# MCU_NAVSS0_UDMASS_ECC_AGGR0_UDMASS_ECCAGGR0 register map
Vendor: Texas Instruments
Registers are 32-bit, access not given, reset 0x0 unless marked. A register's access mark holds for its fields unless they carry their own. Offsets are as the file gives them; [hi:lo] are bit positions; {n}, {i} and the like mark numbered series.

## MCU_NAVSS0_UDMASS_ECC_AGGR0_UDMASS_ECCAGGR0 (part 4 of 4)
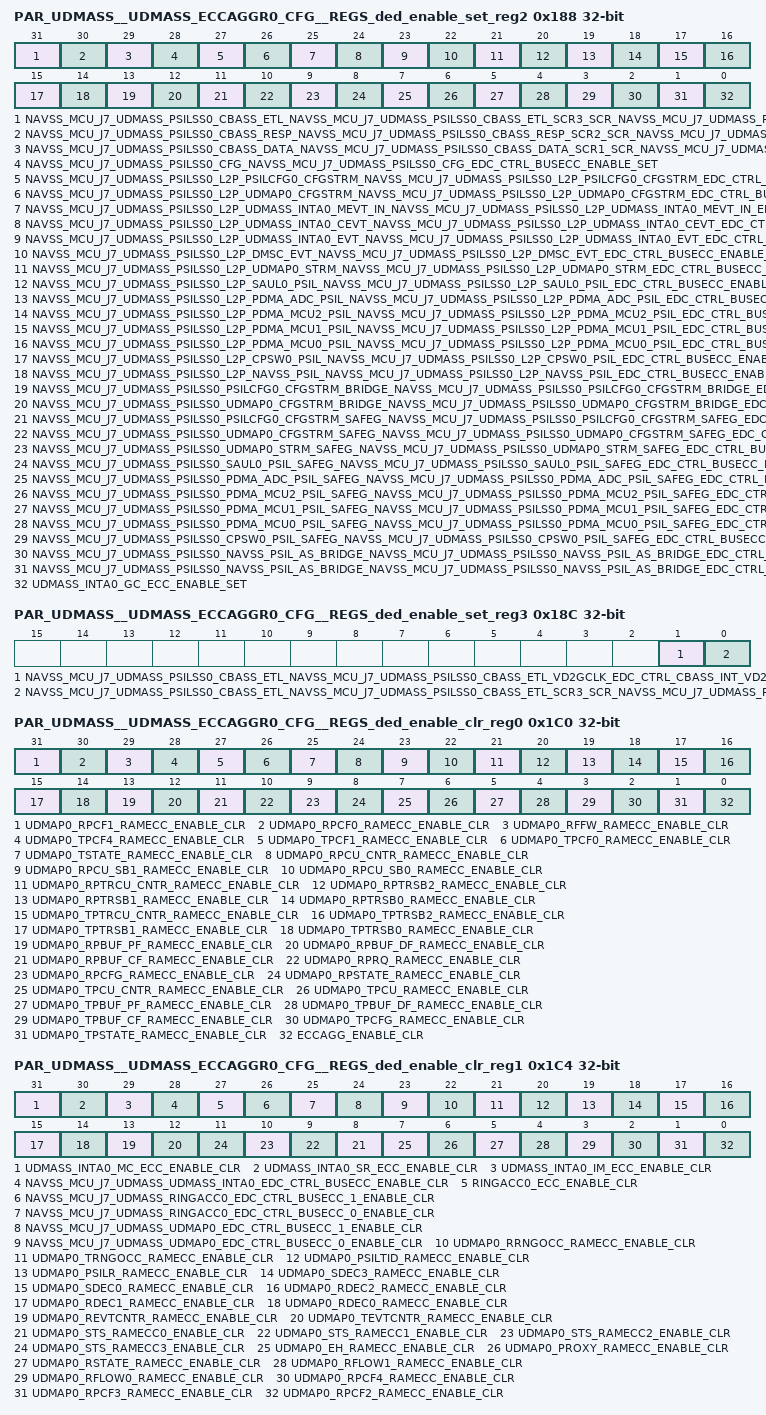
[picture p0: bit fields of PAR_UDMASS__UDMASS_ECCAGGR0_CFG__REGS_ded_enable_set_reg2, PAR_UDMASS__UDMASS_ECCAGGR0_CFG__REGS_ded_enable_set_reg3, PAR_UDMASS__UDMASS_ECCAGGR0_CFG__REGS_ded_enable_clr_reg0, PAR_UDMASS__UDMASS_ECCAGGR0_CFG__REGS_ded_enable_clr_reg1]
0x188 PAR_UDMASS__UDMASS_ECCAGGR0_CFG__REGS_ded_enable_set_reg2 — Interrupt Enable Set Register 2
  [31] NAVSS_MCU_J7_UDMASS_PSILSS0_CBASS_ETL_NAVSS_MCU_J7_UDMASS_PSILSS0_CBASS_ETL_SCR3_SCR_NAVSS_MCU_J7_UDMASS_PSILSS0_CBASS_ETL_SCR3_SCR_EDC_CTRL_BUSECC_0_ENABLE_SET — Interrupt Enable Set Register for navss_mcu_j7_udmass_psilss0_cbass_etl_navss_mcu_j7_udmass_psilss0_cbass_etl_scr3_scr_navss_mcu_j7_udmass_psilss0_cbass_etl_scr3_scr_edc_ctrl_busecc_0_pend (access R/W1TS)
  [30] NAVSS_MCU_J7_UDMASS_PSILSS0_CBASS_RESP_NAVSS_MCU_J7_UDMASS_PSILSS0_CBASS_RESP_SCR2_SCR_NAVSS_MCU_J7_UDMASS_PSILSS0_CBASS_RESP_SCR2_SCR_EDC_CTRL_BUSECC_ENABLE_SET — Interrupt Enable Set Register for navss_mcu_j7_udmass_psilss0_cbass_resp_navss_mcu_j7_udmass_psilss0_cbass_resp_scr2_scr_navss_mcu_j7_udmass_psilss0_cbass_resp_scr2_scr_edc_ctrl_busecc_pend (access R/W1TS)
  [29] NAVSS_MCU_J7_UDMASS_PSILSS0_CBASS_DATA_NAVSS_MCU_J7_UDMASS_PSILSS0_CBASS_DATA_SCR1_SCR_NAVSS_MCU_J7_UDMASS_PSILSS0_CBASS_DATA_SCR1_SCR_EDC_CTRL_BUSECC_ENABLE_SET — Interrupt Enable Set Register for navss_mcu_j7_udmass_psilss0_cbass_data_navss_mcu_j7_udmass_psilss0_cbass_data_scr1_scr_navss_mcu_j7_udmass_psilss0_cbass_data_scr1_scr_edc_ctrl_busecc_pend (access R/W1TS)
  [28] NAVSS_MCU_J7_UDMASS_PSILSS0_CFG_NAVSS_MCU_J7_UDMASS_PSILSS0_CFG_EDC_CTRL_BUSECC_ENABLE_SET — Interrupt Enable Set Register for navss_mcu_j7_udmass_psilss0_cfg_navss_mcu_j7_udmass_psilss0_cfg_edc_ctrl_busecc_pend (access R/W1TS)
  [27] NAVSS_MCU_J7_UDMASS_PSILSS0_L2P_PSILCFG0_CFGSTRM_NAVSS_MCU_J7_UDMASS_PSILSS0_L2P_PSILCFG0_CFGSTRM_EDC_CTRL_BUSECC_ENABLE_SET — Interrupt Enable Set Register for navss_mcu_j7_udmass_psilss0_l2p_psilcfg0_cfgstrm_navss_mcu_j7_udmass_psilss0_l2p_psilcfg0_cfgstrm_edc_ctrl_busecc_pend (access R/W1TS)
  [26] NAVSS_MCU_J7_UDMASS_PSILSS0_L2P_UDMAP0_CFGSTRM_NAVSS_MCU_J7_UDMASS_PSILSS0_L2P_UDMAP0_CFGSTRM_EDC_CTRL_BUSECC_ENABLE_SET — Interrupt Enable Set Register for navss_mcu_j7_udmass_psilss0_l2p_udmap0_cfgstrm_navss_mcu_j7_udmass_psilss0_l2p_udmap0_cfgstrm_edc_ctrl_busecc_pend (access R/W1TS)
  [25] NAVSS_MCU_J7_UDMASS_PSILSS0_L2P_UDMASS_INTA0_MEVT_IN_NAVSS_MCU_J7_UDMASS_PSILSS0_L2P_UDMASS_INTA0_MEVT_IN_EDC_CTRL_BUSECC_ENABLE_SET — Interrupt Enable Set Register for navss_mcu_j7_udmass_psilss0_l2p_udmass_inta0_mevt_in_navss_mcu_j7_udmass_psilss0_l2p_udmass_inta0_mevt_in_edc_ctrl_busecc_pend (access R/W1TS)
  [24] NAVSS_MCU_J7_UDMASS_PSILSS0_L2P_UDMASS_INTA0_CEVT_NAVSS_MCU_J7_UDMASS_PSILSS0_L2P_UDMASS_INTA0_CEVT_EDC_CTRL_BUSECC_ENABLE_SET — Interrupt Enable Set Register for navss_mcu_j7_udmass_psilss0_l2p_udmass_inta0_cevt_navss_mcu_j7_udmass_psilss0_l2p_udmass_inta0_cevt_edc_ctrl_busecc_pend (access R/W1TS)
  [23] NAVSS_MCU_J7_UDMASS_PSILSS0_L2P_UDMASS_INTA0_EVT_NAVSS_MCU_J7_UDMASS_PSILSS0_L2P_UDMASS_INTA0_EVT_EDC_CTRL_BUSECC_ENABLE_SET — Interrupt Enable Set Register for navss_mcu_j7_udmass_psilss0_l2p_udmass_inta0_evt_navss_mcu_j7_udmass_psilss0_l2p_udmass_inta0_evt_edc_ctrl_busecc_pend (access R/W1TS)
  [22] NAVSS_MCU_J7_UDMASS_PSILSS0_L2P_DMSC_EVT_NAVSS_MCU_J7_UDMASS_PSILSS0_L2P_DMSC_EVT_EDC_CTRL_BUSECC_ENABLE_SET — Interrupt Enable Set Register for navss_mcu_j7_udmass_psilss0_l2p_dmsc_evt_navss_mcu_j7_udmass_psilss0_l2p_dmsc_evt_edc_ctrl_busecc_pend (access R/W1TS)
  [21] NAVSS_MCU_J7_UDMASS_PSILSS0_L2P_UDMAP0_STRM_NAVSS_MCU_J7_UDMASS_PSILSS0_L2P_UDMAP0_STRM_EDC_CTRL_BUSECC_ENABLE_SET — Interrupt Enable Set Register for navss_mcu_j7_udmass_psilss0_l2p_udmap0_strm_navss_mcu_j7_udmass_psilss0_l2p_udmap0_strm_edc_ctrl_busecc_pend (access R/W1TS)
  [20] NAVSS_MCU_J7_UDMASS_PSILSS0_L2P_SAUL0_PSIL_NAVSS_MCU_J7_UDMASS_PSILSS0_L2P_SAUL0_PSIL_EDC_CTRL_BUSECC_ENABLE_SET — Interrupt Enable Set Register for navss_mcu_j7_udmass_psilss0_l2p_saul0_psil_navss_mcu_j7_udmass_psilss0_l2p_saul0_psil_edc_ctrl_busecc_pend (access R/W1TS)
  [19] NAVSS_MCU_J7_UDMASS_PSILSS0_L2P_PDMA_ADC_PSIL_NAVSS_MCU_J7_UDMASS_PSILSS0_L2P_PDMA_ADC_PSIL_EDC_CTRL_BUSECC_ENABLE_SET — Interrupt Enable Set Register for navss_mcu_j7_udmass_psilss0_l2p_pdma_adc_psil_navss_mcu_j7_udmass_psilss0_l2p_pdma_adc_psil_edc_ctrl_busecc_pend (access R/W1TS)
  [18] NAVSS_MCU_J7_UDMASS_PSILSS0_L2P_PDMA_MCU2_PSIL_NAVSS_MCU_J7_UDMASS_PSILSS0_L2P_PDMA_MCU2_PSIL_EDC_CTRL_BUSECC_ENABLE_SET — Interrupt Enable Set Register for navss_mcu_j7_udmass_psilss0_l2p_pdma_mcu2_psil_navss_mcu_j7_udmass_psilss0_l2p_pdma_mcu2_psil_edc_ctrl_busecc_pend (access R/W1TS)
  [17] NAVSS_MCU_J7_UDMASS_PSILSS0_L2P_PDMA_MCU1_PSIL_NAVSS_MCU_J7_UDMASS_PSILSS0_L2P_PDMA_MCU1_PSIL_EDC_CTRL_BUSECC_ENABLE_SET — Interrupt Enable Set Register for navss_mcu_j7_udmass_psilss0_l2p_pdma_mcu1_psil_navss_mcu_j7_udmass_psilss0_l2p_pdma_mcu1_psil_edc_ctrl_busecc_pend (access R/W1TS)
  [16] NAVSS_MCU_J7_UDMASS_PSILSS0_L2P_PDMA_MCU0_PSIL_NAVSS_MCU_J7_UDMASS_PSILSS0_L2P_PDMA_MCU0_PSIL_EDC_CTRL_BUSECC_ENABLE_SET — Interrupt Enable Set Register for navss_mcu_j7_udmass_psilss0_l2p_pdma_mcu0_psil_navss_mcu_j7_udmass_psilss0_l2p_pdma_mcu0_psil_edc_ctrl_busecc_pend (access R/W1TS)
  [15] NAVSS_MCU_J7_UDMASS_PSILSS0_L2P_CPSW0_PSIL_NAVSS_MCU_J7_UDMASS_PSILSS0_L2P_CPSW0_PSIL_EDC_CTRL_BUSECC_ENABLE_SET — Interrupt Enable Set Register for navss_mcu_j7_udmass_psilss0_l2p_cpsw0_psil_navss_mcu_j7_udmass_psilss0_l2p_cpsw0_psil_edc_ctrl_busecc_pend (access R/W1TS)
  [14] NAVSS_MCU_J7_UDMASS_PSILSS0_L2P_NAVSS_PSIL_NAVSS_MCU_J7_UDMASS_PSILSS0_L2P_NAVSS_PSIL_EDC_CTRL_BUSECC_ENABLE_SET — Interrupt Enable Set Register for navss_mcu_j7_udmass_psilss0_l2p_navss_psil_navss_mcu_j7_udmass_psilss0_l2p_navss_psil_edc_ctrl_busecc_pend (access R/W1TS)
  [13] NAVSS_MCU_J7_UDMASS_PSILSS0_PSILCFG0_CFGSTRM_BRIDGE_NAVSS_MCU_J7_UDMASS_PSILSS0_PSILCFG0_CFGSTRM_BRIDGE_EDC_CTRL_BUSECC_ENABLE_SET — Interrupt Enable Set Register for navss_mcu_j7_udmass_psilss0_psilcfg0_cfgstrm_bridge_navss_mcu_j7_udmass_psilss0_psilcfg0_cfgstrm_bridge_edc_ctrl_busecc_pend (access R/W1TS)
  [12] NAVSS_MCU_J7_UDMASS_PSILSS0_UDMAP0_CFGSTRM_BRIDGE_NAVSS_MCU_J7_UDMASS_PSILSS0_UDMAP0_CFGSTRM_BRIDGE_EDC_CTRL_BUSECC_ENABLE_SET — Interrupt Enable Set Register for navss_mcu_j7_udmass_psilss0_udmap0_cfgstrm_bridge_navss_mcu_j7_udmass_psilss0_udmap0_cfgstrm_bridge_edc_ctrl_busecc_pend (access R/W1TS)
  [11] NAVSS_MCU_J7_UDMASS_PSILSS0_PSILCFG0_CFGSTRM_SAFEG_NAVSS_MCU_J7_UDMASS_PSILSS0_PSILCFG0_CFGSTRM_SAFEG_EDC_CTRL_BUSECC_ENABLE_SET — Interrupt Enable Set Register for navss_mcu_j7_udmass_psilss0_psilcfg0_cfgstrm_safeg_navss_mcu_j7_udmass_psilss0_psilcfg0_cfgstrm_safeg_edc_ctrl_busecc_pend (access R/W1TS)
  [10] NAVSS_MCU_J7_UDMASS_PSILSS0_UDMAP0_CFGSTRM_SAFEG_NAVSS_MCU_J7_UDMASS_PSILSS0_UDMAP0_CFGSTRM_SAFEG_EDC_CTRL_BUSECC_ENABLE_SET — Interrupt Enable Set Register for navss_mcu_j7_udmass_psilss0_udmap0_cfgstrm_safeg_navss_mcu_j7_udmass_psilss0_udmap0_cfgstrm_safeg_edc_ctrl_busecc_pend (access R/W1TS)
  [9] NAVSS_MCU_J7_UDMASS_PSILSS0_UDMAP0_STRM_SAFEG_NAVSS_MCU_J7_UDMASS_PSILSS0_UDMAP0_STRM_SAFEG_EDC_CTRL_BUSECC_ENABLE_SET — Interrupt Enable Set Register for navss_mcu_j7_udmass_psilss0_udmap0_strm_safeg_navss_mcu_j7_udmass_psilss0_udmap0_strm_safeg_edc_ctrl_busecc_pend (access R/W1TS)
  [8] NAVSS_MCU_J7_UDMASS_PSILSS0_SAUL0_PSIL_SAFEG_NAVSS_MCU_J7_UDMASS_PSILSS0_SAUL0_PSIL_SAFEG_EDC_CTRL_BUSECC_ENABLE_SET — Interrupt Enable Set Register for navss_mcu_j7_udmass_psilss0_saul0_psil_safeg_navss_mcu_j7_udmass_psilss0_saul0_psil_safeg_edc_ctrl_busecc_pend (access R/W1TS)
  [7] NAVSS_MCU_J7_UDMASS_PSILSS0_PDMA_ADC_PSIL_SAFEG_NAVSS_MCU_J7_UDMASS_PSILSS0_PDMA_ADC_PSIL_SAFEG_EDC_CTRL_BUSECC_ENABLE_SET — Interrupt Enable Set Register for navss_mcu_j7_udmass_psilss0_pdma_adc_psil_safeg_navss_mcu_j7_udmass_psilss0_pdma_adc_psil_safeg_edc_ctrl_busecc_pend (access R/W1TS)
  [6] NAVSS_MCU_J7_UDMASS_PSILSS0_PDMA_MCU2_PSIL_SAFEG_NAVSS_MCU_J7_UDMASS_PSILSS0_PDMA_MCU2_PSIL_SAFEG_EDC_CTRL_BUSECC_ENABLE_SET — Interrupt Enable Set Register for navss_mcu_j7_udmass_psilss0_pdma_mcu2_psil_safeg_navss_mcu_j7_udmass_psilss0_pdma_mcu2_psil_safeg_edc_ctrl_busecc_pend (access R/W1TS)
  [5] NAVSS_MCU_J7_UDMASS_PSILSS0_PDMA_MCU1_PSIL_SAFEG_NAVSS_MCU_J7_UDMASS_PSILSS0_PDMA_MCU1_PSIL_SAFEG_EDC_CTRL_BUSECC_ENABLE_SET — Interrupt Enable Set Register for navss_mcu_j7_udmass_psilss0_pdma_mcu1_psil_safeg_navss_mcu_j7_udmass_psilss0_pdma_mcu1_psil_safeg_edc_ctrl_busecc_pend (access R/W1TS)
  [4] NAVSS_MCU_J7_UDMASS_PSILSS0_PDMA_MCU0_PSIL_SAFEG_NAVSS_MCU_J7_UDMASS_PSILSS0_PDMA_MCU0_PSIL_SAFEG_EDC_CTRL_BUSECC_ENABLE_SET — Interrupt Enable Set Register for navss_mcu_j7_udmass_psilss0_pdma_mcu0_psil_safeg_navss_mcu_j7_udmass_psilss0_pdma_mcu0_psil_safeg_edc_ctrl_busecc_pend (access R/W1TS)
  [3] NAVSS_MCU_J7_UDMASS_PSILSS0_CPSW0_PSIL_SAFEG_NAVSS_MCU_J7_UDMASS_PSILSS0_CPSW0_PSIL_SAFEG_EDC_CTRL_BUSECC_ENABLE_SET — Interrupt Enable Set Register for navss_mcu_j7_udmass_psilss0_cpsw0_psil_safeg_navss_mcu_j7_udmass_psilss0_cpsw0_psil_safeg_edc_ctrl_busecc_pend (access R/W1TS)
  [2] NAVSS_MCU_J7_UDMASS_PSILSS0_NAVSS_PSIL_AS_BRIDGE_NAVSS_MCU_J7_UDMASS_PSILSS0_NAVSS_PSIL_AS_BRIDGE_EDC_CTRL_NAVSS_PSIL_SCR_E_GCLK_BUSECC_ENABLE_SET — Interrupt Enable Set Register for navss_mcu_j7_udmass_psilss0_navss_psil_as_bridge_navss_mcu_j7_udmass_psilss0_navss_psil_as_bridge_edc_ctrl_navss_psil_scr_e_gclk_busecc_pend (access R/W1TS)
  [1] NAVSS_MCU_J7_UDMASS_PSILSS0_NAVSS_PSIL_AS_BRIDGE_NAVSS_MCU_J7_UDMASS_PSILSS0_NAVSS_PSIL_AS_BRIDGE_EDC_CTRL_NAVSS_PSIL_E_GCLK_BUSECC_ENABLE_SET — Interrupt Enable Set Register for navss_mcu_j7_udmass_psilss0_navss_psil_as_bridge_navss_mcu_j7_udmass_psilss0_navss_psil_as_bridge_edc_ctrl_navss_psil_e_gclk_busecc_pend (access R/W1TS)
  [0] UDMASS_INTA0_GC_ECC_ENABLE_SET — Interrupt Enable Set Register for udmass_inta0_gc_ecc_pend (access R/W1TS)
0x18C PAR_UDMASS__UDMASS_ECCAGGR0_CFG__REGS_ded_enable_set_reg3 — Interrupt Enable Set Register 3
  [1] NAVSS_MCU_J7_UDMASS_PSILSS0_CBASS_ETL_NAVSS_MCU_J7_UDMASS_PSILSS0_CBASS_ETL_VD2GCLK_EDC_CTRL_CBASS_INT_VD2GBUSECC_ENABLE_SET — Interrupt Enable Set Register for navss_mcu_j7_udmass_psilss0_cbass_etl_navss_mcu_j7_udmass_psilss0_cbass_etl_vd2gclk_edc_ctrl_cbass_int_vd2gbusecc_pend (access R/W1TS)
  [0] NAVSS_MCU_J7_UDMASS_PSILSS0_CBASS_ETL_NAVSS_MCU_J7_UDMASS_PSILSS0_CBASS_ETL_SCR3_SCR_NAVSS_MCU_J7_UDMASS_PSILSS0_CBASS_ETL_SCR3_SCR_EDC_CTRL_BUSECC_1_ENABLE_SET — Interrupt Enable Set Register for navss_mcu_j7_udmass_psilss0_cbass_etl_navss_mcu_j7_udmass_psilss0_cbass_etl_scr3_scr_navss_mcu_j7_udmass_psilss0_cbass_etl_scr3_scr_edc_ctrl_busecc_1_pend (access R/W1TS)
0x1C0 PAR_UDMASS__UDMASS_ECCAGGR0_CFG__REGS_ded_enable_clr_reg0 — Interrupt Enable Clear Register 0
  [31] UDMAP0_RPCF1_RAMECC_ENABLE_CLR — Interrupt Enable Clear Register for udmap0_rpcf1_ramecc_pend (access R/W1TC)
  [30] UDMAP0_RPCF0_RAMECC_ENABLE_CLR — Interrupt Enable Clear Register for udmap0_rpcf0_ramecc_pend (access R/W1TC)
  [29] UDMAP0_RFFW_RAMECC_ENABLE_CLR — Interrupt Enable Clear Register for udmap0_rffw_ramecc_pend (access R/W1TC)
  [28] UDMAP0_TPCF4_RAMECC_ENABLE_CLR — Interrupt Enable Clear Register for udmap0_tpcf4_ramecc_pend (access R/W1TC)
  [27] UDMAP0_TPCF1_RAMECC_ENABLE_CLR — Interrupt Enable Clear Register for udmap0_tpcf1_ramecc_pend (access R/W1TC)
  [26] UDMAP0_TPCF0_RAMECC_ENABLE_CLR — Interrupt Enable Clear Register for udmap0_tpcf0_ramecc_pend (access R/W1TC)
  [25] UDMAP0_TSTATE_RAMECC_ENABLE_CLR — Interrupt Enable Clear Register for udmap0_tstate_ramecc_pend (access R/W1TC)
  [24] UDMAP0_RPCU_CNTR_RAMECC_ENABLE_CLR — Interrupt Enable Clear Register for udmap0_rpcu_cntr_ramecc_pend (access R/W1TC)
  [23] UDMAP0_RPCU_SB1_RAMECC_ENABLE_CLR — Interrupt Enable Clear Register for udmap0_rpcu_sb1_ramecc_pend (access R/W1TC)
  [22] UDMAP0_RPCU_SB0_RAMECC_ENABLE_CLR — Interrupt Enable Clear Register for udmap0_rpcu_sb0_ramecc_pend (access R/W1TC)
  [21] UDMAP0_RPTRCU_CNTR_RAMECC_ENABLE_CLR — Interrupt Enable Clear Register for udmap0_rptrcu_cntr_ramecc_pend (access R/W1TC)
  [20] UDMAP0_RPTRSB2_RAMECC_ENABLE_CLR — Interrupt Enable Clear Register for udmap0_rptrsb2_ramecc_pend (access R/W1TC)
  [19] UDMAP0_RPTRSB1_RAMECC_ENABLE_CLR — Interrupt Enable Clear Register for udmap0_rptrsb1_ramecc_pend (access R/W1TC)
  [18] UDMAP0_RPTRSB0_RAMECC_ENABLE_CLR — Interrupt Enable Clear Register for udmap0_rptrsb0_ramecc_pend (access R/W1TC)
  [17] UDMAP0_TPTRCU_CNTR_RAMECC_ENABLE_CLR — Interrupt Enable Clear Register for udmap0_tptrcu_cntr_ramecc_pend (access R/W1TC)
  [16] UDMAP0_TPTRSB2_RAMECC_ENABLE_CLR — Interrupt Enable Clear Register for udmap0_tptrsb2_ramecc_pend (access R/W1TC)
  [15] UDMAP0_TPTRSB1_RAMECC_ENABLE_CLR — Interrupt Enable Clear Register for udmap0_tptrsb1_ramecc_pend (access R/W1TC)
  [14] UDMAP0_TPTRSB0_RAMECC_ENABLE_CLR — Interrupt Enable Clear Register for udmap0_tptrsb0_ramecc_pend (access R/W1TC)
  [13] UDMAP0_RPBUF_PF_RAMECC_ENABLE_CLR — Interrupt Enable Clear Register for udmap0_rpbuf_pf_ramecc_pend (access R/W1TC)
  [12] UDMAP0_RPBUF_DF_RAMECC_ENABLE_CLR — Interrupt Enable Clear Register for udmap0_rpbuf_df_ramecc_pend (access R/W1TC)
  [11] UDMAP0_RPBUF_CF_RAMECC_ENABLE_CLR — Interrupt Enable Clear Register for udmap0_rpbuf_cf_ramecc_pend (access R/W1TC)
  [10] UDMAP0_RPRQ_RAMECC_ENABLE_CLR — Interrupt Enable Clear Register for udmap0_rprq_ramecc_pend (access R/W1TC)
  [9] UDMAP0_RPCFG_RAMECC_ENABLE_CLR — Interrupt Enable Clear Register for udmap0_rpcfg_ramecc_pend (access R/W1TC)
  [8] UDMAP0_RPSTATE_RAMECC_ENABLE_CLR — Interrupt Enable Clear Register for udmap0_rpstate_ramecc_pend (access R/W1TC)
  [7] UDMAP0_TPCU_CNTR_RAMECC_ENABLE_CLR — Interrupt Enable Clear Register for udmap0_tpcu_cntr_ramecc_pend (access R/W1TC)
  [6] UDMAP0_TPCU_RAMECC_ENABLE_CLR — Interrupt Enable Clear Register for udmap0_tpcu_ramecc_pend (access R/W1TC)
  [5] UDMAP0_TPBUF_PF_RAMECC_ENABLE_CLR — Interrupt Enable Clear Register for udmap0_tpbuf_pf_ramecc_pend (access R/W1TC)
  [4] UDMAP0_TPBUF_DF_RAMECC_ENABLE_CLR — Interrupt Enable Clear Register for udmap0_tpbuf_df_ramecc_pend (access R/W1TC)
  [3] UDMAP0_TPBUF_CF_RAMECC_ENABLE_CLR — Interrupt Enable Clear Register for udmap0_tpbuf_cf_ramecc_pend (access R/W1TC)
  [2] UDMAP0_TPCFG_RAMECC_ENABLE_CLR — Interrupt Enable Clear Register for udmap0_tpcfg_ramecc_pend (access R/W1TC)
  [1] UDMAP0_TPSTATE_RAMECC_ENABLE_CLR — Interrupt Enable Clear Register for udmap0_tpstate_ramecc_pend (access R/W1TC)
  [0] ECCAGG_ENABLE_CLR — Interrupt Enable Clear Register for eccagg_pend (access R/W1TC)
0x1C4 PAR_UDMASS__UDMASS_ECCAGGR0_CFG__REGS_ded_enable_clr_reg1 — Interrupt Enable Clear Register 1
  [31] UDMASS_INTA0_MC_ECC_ENABLE_CLR — Interrupt Enable Clear Register for udmass_inta0_mc_ecc_pend (access R/W1TC)
  [30] UDMASS_INTA0_SR_ECC_ENABLE_CLR — Interrupt Enable Clear Register for udmass_inta0_sr_ecc_pend (access R/W1TC)
  [29] UDMASS_INTA0_IM_ECC_ENABLE_CLR — Interrupt Enable Clear Register for udmass_inta0_im_ecc_pend (access R/W1TC)
  [28] NAVSS_MCU_J7_UDMASS_UDMASS_INTA0_EDC_CTRL_BUSECC_ENABLE_CLR — Interrupt Enable Clear Register for navss_mcu_j7_udmass_udmass_inta0_edc_ctrl_busecc_pend (access R/W1TC)
  [27] RINGACC0_ECC_ENABLE_CLR — Interrupt Enable Clear Register for ringacc0_ecc_pend (access R/W1TC)
  [26] NAVSS_MCU_J7_UDMASS_RINGACC0_EDC_CTRL_BUSECC_1_ENABLE_CLR — Interrupt Enable Clear Register for navss_mcu_j7_udmass_ringacc0_edc_ctrl_busecc_1_pend (access R/W1TC)
  [25] NAVSS_MCU_J7_UDMASS_RINGACC0_EDC_CTRL_BUSECC_0_ENABLE_CLR — Interrupt Enable Clear Register for navss_mcu_j7_udmass_ringacc0_edc_ctrl_busecc_0_pend (access R/W1TC)
  [24] NAVSS_MCU_J7_UDMASS_UDMAP0_EDC_CTRL_BUSECC_1_ENABLE_CLR — Interrupt Enable Clear Register for navss_mcu_j7_udmass_udmap0_edc_ctrl_busecc_1_pend (access R/W1TC)
  [23] NAVSS_MCU_J7_UDMASS_UDMAP0_EDC_CTRL_BUSECC_0_ENABLE_CLR — Interrupt Enable Clear Register for navss_mcu_j7_udmass_udmap0_edc_ctrl_busecc_0_pend (access R/W1TC)
  [22] UDMAP0_RRNGOCC_RAMECC_ENABLE_CLR — Interrupt Enable Clear Register for udmap0_rrngocc_ramecc_pend (access R/W1TC)
  [21] UDMAP0_TRNGOCC_RAMECC_ENABLE_CLR — Interrupt Enable Clear Register for udmap0_trngocc_ramecc_pend (access R/W1TC)
  [20] UDMAP0_PSILTID_RAMECC_ENABLE_CLR — Interrupt Enable Clear Register for udmap0_psiltid_ramecc_pend (access R/W1TC)
  [19] UDMAP0_PSILR_RAMECC_ENABLE_CLR — Interrupt Enable Clear Register for udmap0_psilr_ramecc_pend (access R/W1TC)
  [18] UDMAP0_SDEC3_RAMECC_ENABLE_CLR — Interrupt Enable Clear Register for udmap0_sdec3_ramecc_pend (access R/W1TC)
  [17] UDMAP0_SDEC0_RAMECC_ENABLE_CLR — Interrupt Enable Clear Register for udmap0_sdec0_ramecc_pend (access R/W1TC)
  [16] UDMAP0_RDEC2_RAMECC_ENABLE_CLR — Interrupt Enable Clear Register for udmap0_rdec2_ramecc_pend (access R/W1TC)
  [15] UDMAP0_RDEC1_RAMECC_ENABLE_CLR — Interrupt Enable Clear Register for udmap0_rdec1_ramecc_pend (access R/W1TC)
  [14] UDMAP0_RDEC0_RAMECC_ENABLE_CLR — Interrupt Enable Clear Register for udmap0_rdec0_ramecc_pend (access R/W1TC)
  [13] UDMAP0_REVTCNTR_RAMECC_ENABLE_CLR — Interrupt Enable Clear Register for udmap0_revtcntr_ramecc_pend (access R/W1TC)
  [12] UDMAP0_TEVTCNTR_RAMECC_ENABLE_CLR — Interrupt Enable Clear Register for udmap0_tevtcntr_ramecc_pend (access R/W1TC)
  [n+8] UDMAP0_STS_RAMECC{n}_ENABLE_CLR (n=0..3) — Interrupt Enable Clear Register for udmap0_sts_ramecc{n}_pend (access R/W1TC)
  [7] UDMAP0_EH_RAMECC_ENABLE_CLR — Interrupt Enable Clear Register for udmap0_eh_ramecc_pend (access R/W1TC)
  [6] UDMAP0_PROXY_RAMECC_ENABLE_CLR — Interrupt Enable Clear Register for udmap0_proxy_ramecc_pend (access R/W1TC)
  [5] UDMAP0_RSTATE_RAMECC_ENABLE_CLR — Interrupt Enable Clear Register for udmap0_rstate_ramecc_pend (access R/W1TC)
  [4] UDMAP0_RFLOW1_RAMECC_ENABLE_CLR — Interrupt Enable Clear Register for udmap0_rflow1_ramecc_pend (access R/W1TC)
  [3] UDMAP0_RFLOW0_RAMECC_ENABLE_CLR — Interrupt Enable Clear Register for udmap0_rflow0_ramecc_pend (access R/W1TC)
  [2] UDMAP0_RPCF4_RAMECC_ENABLE_CLR — Interrupt Enable Clear Register for udmap0_rpcf4_ramecc_pend (access R/W1TC)
  [1] UDMAP0_RPCF3_RAMECC_ENABLE_CLR — Interrupt Enable Clear Register for udmap0_rpcf3_ramecc_pend (access R/W1TC)
  [0] UDMAP0_RPCF2_RAMECC_ENABLE_CLR — Interrupt Enable Clear Register for udmap0_rpcf2_ramecc_pend (access R/W1TC)
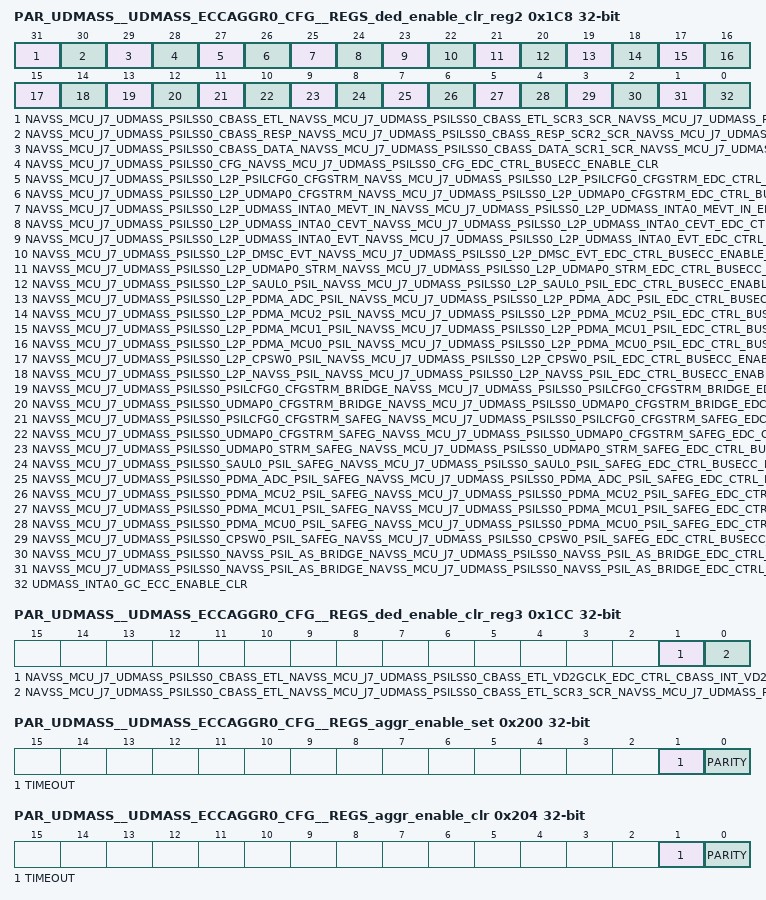
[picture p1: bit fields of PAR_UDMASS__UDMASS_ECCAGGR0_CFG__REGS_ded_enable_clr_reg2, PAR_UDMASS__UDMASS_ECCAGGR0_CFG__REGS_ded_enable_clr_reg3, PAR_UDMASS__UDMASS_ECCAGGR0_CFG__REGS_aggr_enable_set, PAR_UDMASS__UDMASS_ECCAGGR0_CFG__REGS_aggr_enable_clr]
0x1C8 PAR_UDMASS__UDMASS_ECCAGGR0_CFG__REGS_ded_enable_clr_reg2 — Interrupt Enable Clear Register 2
  [31] NAVSS_MCU_J7_UDMASS_PSILSS0_CBASS_ETL_NAVSS_MCU_J7_UDMASS_PSILSS0_CBASS_ETL_SCR3_SCR_NAVSS_MCU_J7_UDMASS_PSILSS0_CBASS_ETL_SCR3_SCR_EDC_CTRL_BUSECC_0_ENABLE_CLR — Interrupt Enable Clear Register for navss_mcu_j7_udmass_psilss0_cbass_etl_navss_mcu_j7_udmass_psilss0_cbass_etl_scr3_scr_navss_mcu_j7_udmass_psilss0_cbass_etl_scr3_scr_edc_ctrl_busecc_0_pend (access R/W1TC)
  [30] NAVSS_MCU_J7_UDMASS_PSILSS0_CBASS_RESP_NAVSS_MCU_J7_UDMASS_PSILSS0_CBASS_RESP_SCR2_SCR_NAVSS_MCU_J7_UDMASS_PSILSS0_CBASS_RESP_SCR2_SCR_EDC_CTRL_BUSECC_ENABLE_CLR — Interrupt Enable Clear Register for navss_mcu_j7_udmass_psilss0_cbass_resp_navss_mcu_j7_udmass_psilss0_cbass_resp_scr2_scr_navss_mcu_j7_udmass_psilss0_cbass_resp_scr2_scr_edc_ctrl_busecc_pend (access R/W1TC)
  [29] NAVSS_MCU_J7_UDMASS_PSILSS0_CBASS_DATA_NAVSS_MCU_J7_UDMASS_PSILSS0_CBASS_DATA_SCR1_SCR_NAVSS_MCU_J7_UDMASS_PSILSS0_CBASS_DATA_SCR1_SCR_EDC_CTRL_BUSECC_ENABLE_CLR — Interrupt Enable Clear Register for navss_mcu_j7_udmass_psilss0_cbass_data_navss_mcu_j7_udmass_psilss0_cbass_data_scr1_scr_navss_mcu_j7_udmass_psilss0_cbass_data_scr1_scr_edc_ctrl_busecc_pend (access R/W1TC)
  [28] NAVSS_MCU_J7_UDMASS_PSILSS0_CFG_NAVSS_MCU_J7_UDMASS_PSILSS0_CFG_EDC_CTRL_BUSECC_ENABLE_CLR — Interrupt Enable Clear Register for navss_mcu_j7_udmass_psilss0_cfg_navss_mcu_j7_udmass_psilss0_cfg_edc_ctrl_busecc_pend (access R/W1TC)
  [27] NAVSS_MCU_J7_UDMASS_PSILSS0_L2P_PSILCFG0_CFGSTRM_NAVSS_MCU_J7_UDMASS_PSILSS0_L2P_PSILCFG0_CFGSTRM_EDC_CTRL_BUSECC_ENABLE_CLR — Interrupt Enable Clear Register for navss_mcu_j7_udmass_psilss0_l2p_psilcfg0_cfgstrm_navss_mcu_j7_udmass_psilss0_l2p_psilcfg0_cfgstrm_edc_ctrl_busecc_pend (access R/W1TC)
  [26] NAVSS_MCU_J7_UDMASS_PSILSS0_L2P_UDMAP0_CFGSTRM_NAVSS_MCU_J7_UDMASS_PSILSS0_L2P_UDMAP0_CFGSTRM_EDC_CTRL_BUSECC_ENABLE_CLR — Interrupt Enable Clear Register for navss_mcu_j7_udmass_psilss0_l2p_udmap0_cfgstrm_navss_mcu_j7_udmass_psilss0_l2p_udmap0_cfgstrm_edc_ctrl_busecc_pend (access R/W1TC)
  [25] NAVSS_MCU_J7_UDMASS_PSILSS0_L2P_UDMASS_INTA0_MEVT_IN_NAVSS_MCU_J7_UDMASS_PSILSS0_L2P_UDMASS_INTA0_MEVT_IN_EDC_CTRL_BUSECC_ENABLE_CLR — Interrupt Enable Clear Register for navss_mcu_j7_udmass_psilss0_l2p_udmass_inta0_mevt_in_navss_mcu_j7_udmass_psilss0_l2p_udmass_inta0_mevt_in_edc_ctrl_busecc_pend (access R/W1TC)
  [24] NAVSS_MCU_J7_UDMASS_PSILSS0_L2P_UDMASS_INTA0_CEVT_NAVSS_MCU_J7_UDMASS_PSILSS0_L2P_UDMASS_INTA0_CEVT_EDC_CTRL_BUSECC_ENABLE_CLR — Interrupt Enable Clear Register for navss_mcu_j7_udmass_psilss0_l2p_udmass_inta0_cevt_navss_mcu_j7_udmass_psilss0_l2p_udmass_inta0_cevt_edc_ctrl_busecc_pend (access R/W1TC)
  [23] NAVSS_MCU_J7_UDMASS_PSILSS0_L2P_UDMASS_INTA0_EVT_NAVSS_MCU_J7_UDMASS_PSILSS0_L2P_UDMASS_INTA0_EVT_EDC_CTRL_BUSECC_ENABLE_CLR — Interrupt Enable Clear Register for navss_mcu_j7_udmass_psilss0_l2p_udmass_inta0_evt_navss_mcu_j7_udmass_psilss0_l2p_udmass_inta0_evt_edc_ctrl_busecc_pend (access R/W1TC)
  [22] NAVSS_MCU_J7_UDMASS_PSILSS0_L2P_DMSC_EVT_NAVSS_MCU_J7_UDMASS_PSILSS0_L2P_DMSC_EVT_EDC_CTRL_BUSECC_ENABLE_CLR — Interrupt Enable Clear Register for navss_mcu_j7_udmass_psilss0_l2p_dmsc_evt_navss_mcu_j7_udmass_psilss0_l2p_dmsc_evt_edc_ctrl_busecc_pend (access R/W1TC)
  [21] NAVSS_MCU_J7_UDMASS_PSILSS0_L2P_UDMAP0_STRM_NAVSS_MCU_J7_UDMASS_PSILSS0_L2P_UDMAP0_STRM_EDC_CTRL_BUSECC_ENABLE_CLR — Interrupt Enable Clear Register for navss_mcu_j7_udmass_psilss0_l2p_udmap0_strm_navss_mcu_j7_udmass_psilss0_l2p_udmap0_strm_edc_ctrl_busecc_pend (access R/W1TC)
  [20] NAVSS_MCU_J7_UDMASS_PSILSS0_L2P_SAUL0_PSIL_NAVSS_MCU_J7_UDMASS_PSILSS0_L2P_SAUL0_PSIL_EDC_CTRL_BUSECC_ENABLE_CLR — Interrupt Enable Clear Register for navss_mcu_j7_udmass_psilss0_l2p_saul0_psil_navss_mcu_j7_udmass_psilss0_l2p_saul0_psil_edc_ctrl_busecc_pend (access R/W1TC)
  [19] NAVSS_MCU_J7_UDMASS_PSILSS0_L2P_PDMA_ADC_PSIL_NAVSS_MCU_J7_UDMASS_PSILSS0_L2P_PDMA_ADC_PSIL_EDC_CTRL_BUSECC_ENABLE_CLR — Interrupt Enable Clear Register for navss_mcu_j7_udmass_psilss0_l2p_pdma_adc_psil_navss_mcu_j7_udmass_psilss0_l2p_pdma_adc_psil_edc_ctrl_busecc_pend (access R/W1TC)
  [18] NAVSS_MCU_J7_UDMASS_PSILSS0_L2P_PDMA_MCU2_PSIL_NAVSS_MCU_J7_UDMASS_PSILSS0_L2P_PDMA_MCU2_PSIL_EDC_CTRL_BUSECC_ENABLE_CLR — Interrupt Enable Clear Register for navss_mcu_j7_udmass_psilss0_l2p_pdma_mcu2_psil_navss_mcu_j7_udmass_psilss0_l2p_pdma_mcu2_psil_edc_ctrl_busecc_pend (access R/W1TC)
  [17] NAVSS_MCU_J7_UDMASS_PSILSS0_L2P_PDMA_MCU1_PSIL_NAVSS_MCU_J7_UDMASS_PSILSS0_L2P_PDMA_MCU1_PSIL_EDC_CTRL_BUSECC_ENABLE_CLR — Interrupt Enable Clear Register for navss_mcu_j7_udmass_psilss0_l2p_pdma_mcu1_psil_navss_mcu_j7_udmass_psilss0_l2p_pdma_mcu1_psil_edc_ctrl_busecc_pend (access R/W1TC)
  [16] NAVSS_MCU_J7_UDMASS_PSILSS0_L2P_PDMA_MCU0_PSIL_NAVSS_MCU_J7_UDMASS_PSILSS0_L2P_PDMA_MCU0_PSIL_EDC_CTRL_BUSECC_ENABLE_CLR — Interrupt Enable Clear Register for navss_mcu_j7_udmass_psilss0_l2p_pdma_mcu0_psil_navss_mcu_j7_udmass_psilss0_l2p_pdma_mcu0_psil_edc_ctrl_busecc_pend (access R/W1TC)
  [15] NAVSS_MCU_J7_UDMASS_PSILSS0_L2P_CPSW0_PSIL_NAVSS_MCU_J7_UDMASS_PSILSS0_L2P_CPSW0_PSIL_EDC_CTRL_BUSECC_ENABLE_CLR — Interrupt Enable Clear Register for navss_mcu_j7_udmass_psilss0_l2p_cpsw0_psil_navss_mcu_j7_udmass_psilss0_l2p_cpsw0_psil_edc_ctrl_busecc_pend (access R/W1TC)
  [14] NAVSS_MCU_J7_UDMASS_PSILSS0_L2P_NAVSS_PSIL_NAVSS_MCU_J7_UDMASS_PSILSS0_L2P_NAVSS_PSIL_EDC_CTRL_BUSECC_ENABLE_CLR — Interrupt Enable Clear Register for navss_mcu_j7_udmass_psilss0_l2p_navss_psil_navss_mcu_j7_udmass_psilss0_l2p_navss_psil_edc_ctrl_busecc_pend (access R/W1TC)
  [13] NAVSS_MCU_J7_UDMASS_PSILSS0_PSILCFG0_CFGSTRM_BRIDGE_NAVSS_MCU_J7_UDMASS_PSILSS0_PSILCFG0_CFGSTRM_BRIDGE_EDC_CTRL_BUSECC_ENABLE_CLR — Interrupt Enable Clear Register for navss_mcu_j7_udmass_psilss0_psilcfg0_cfgstrm_bridge_navss_mcu_j7_udmass_psilss0_psilcfg0_cfgstrm_bridge_edc_ctrl_busecc_pend (access R/W1TC)
  [12] NAVSS_MCU_J7_UDMASS_PSILSS0_UDMAP0_CFGSTRM_BRIDGE_NAVSS_MCU_J7_UDMASS_PSILSS0_UDMAP0_CFGSTRM_BRIDGE_EDC_CTRL_BUSECC_ENABLE_CLR — Interrupt Enable Clear Register for navss_mcu_j7_udmass_psilss0_udmap0_cfgstrm_bridge_navss_mcu_j7_udmass_psilss0_udmap0_cfgstrm_bridge_edc_ctrl_busecc_pend (access R/W1TC)
  [11] NAVSS_MCU_J7_UDMASS_PSILSS0_PSILCFG0_CFGSTRM_SAFEG_NAVSS_MCU_J7_UDMASS_PSILSS0_PSILCFG0_CFGSTRM_SAFEG_EDC_CTRL_BUSECC_ENABLE_CLR — Interrupt Enable Clear Register for navss_mcu_j7_udmass_psilss0_psilcfg0_cfgstrm_safeg_navss_mcu_j7_udmass_psilss0_psilcfg0_cfgstrm_safeg_edc_ctrl_busecc_pend (access R/W1TC)
  [10] NAVSS_MCU_J7_UDMASS_PSILSS0_UDMAP0_CFGSTRM_SAFEG_NAVSS_MCU_J7_UDMASS_PSILSS0_UDMAP0_CFGSTRM_SAFEG_EDC_CTRL_BUSECC_ENABLE_CLR — Interrupt Enable Clear Register for navss_mcu_j7_udmass_psilss0_udmap0_cfgstrm_safeg_navss_mcu_j7_udmass_psilss0_udmap0_cfgstrm_safeg_edc_ctrl_busecc_pend (access R/W1TC)
  [9] NAVSS_MCU_J7_UDMASS_PSILSS0_UDMAP0_STRM_SAFEG_NAVSS_MCU_J7_UDMASS_PSILSS0_UDMAP0_STRM_SAFEG_EDC_CTRL_BUSECC_ENABLE_CLR — Interrupt Enable Clear Register for navss_mcu_j7_udmass_psilss0_udmap0_strm_safeg_navss_mcu_j7_udmass_psilss0_udmap0_strm_safeg_edc_ctrl_busecc_pend (access R/W1TC)
  [8] NAVSS_MCU_J7_UDMASS_PSILSS0_SAUL0_PSIL_SAFEG_NAVSS_MCU_J7_UDMASS_PSILSS0_SAUL0_PSIL_SAFEG_EDC_CTRL_BUSECC_ENABLE_CLR — Interrupt Enable Clear Register for navss_mcu_j7_udmass_psilss0_saul0_psil_safeg_navss_mcu_j7_udmass_psilss0_saul0_psil_safeg_edc_ctrl_busecc_pend (access R/W1TC)
  [7] NAVSS_MCU_J7_UDMASS_PSILSS0_PDMA_ADC_PSIL_SAFEG_NAVSS_MCU_J7_UDMASS_PSILSS0_PDMA_ADC_PSIL_SAFEG_EDC_CTRL_BUSECC_ENABLE_CLR — Interrupt Enable Clear Register for navss_mcu_j7_udmass_psilss0_pdma_adc_psil_safeg_navss_mcu_j7_udmass_psilss0_pdma_adc_psil_safeg_edc_ctrl_busecc_pend (access R/W1TC)
  [6] NAVSS_MCU_J7_UDMASS_PSILSS0_PDMA_MCU2_PSIL_SAFEG_NAVSS_MCU_J7_UDMASS_PSILSS0_PDMA_MCU2_PSIL_SAFEG_EDC_CTRL_BUSECC_ENABLE_CLR — Interrupt Enable Clear Register for navss_mcu_j7_udmass_psilss0_pdma_mcu2_psil_safeg_navss_mcu_j7_udmass_psilss0_pdma_mcu2_psil_safeg_edc_ctrl_busecc_pend (access R/W1TC)
  [5] NAVSS_MCU_J7_UDMASS_PSILSS0_PDMA_MCU1_PSIL_SAFEG_NAVSS_MCU_J7_UDMASS_PSILSS0_PDMA_MCU1_PSIL_SAFEG_EDC_CTRL_BUSECC_ENABLE_CLR — Interrupt Enable Clear Register for navss_mcu_j7_udmass_psilss0_pdma_mcu1_psil_safeg_navss_mcu_j7_udmass_psilss0_pdma_mcu1_psil_safeg_edc_ctrl_busecc_pend (access R/W1TC)
  [4] NAVSS_MCU_J7_UDMASS_PSILSS0_PDMA_MCU0_PSIL_SAFEG_NAVSS_MCU_J7_UDMASS_PSILSS0_PDMA_MCU0_PSIL_SAFEG_EDC_CTRL_BUSECC_ENABLE_CLR — Interrupt Enable Clear Register for navss_mcu_j7_udmass_psilss0_pdma_mcu0_psil_safeg_navss_mcu_j7_udmass_psilss0_pdma_mcu0_psil_safeg_edc_ctrl_busecc_pend (access R/W1TC)
  [3] NAVSS_MCU_J7_UDMASS_PSILSS0_CPSW0_PSIL_SAFEG_NAVSS_MCU_J7_UDMASS_PSILSS0_CPSW0_PSIL_SAFEG_EDC_CTRL_BUSECC_ENABLE_CLR — Interrupt Enable Clear Register for navss_mcu_j7_udmass_psilss0_cpsw0_psil_safeg_navss_mcu_j7_udmass_psilss0_cpsw0_psil_safeg_edc_ctrl_busecc_pend (access R/W1TC)
  [2] NAVSS_MCU_J7_UDMASS_PSILSS0_NAVSS_PSIL_AS_BRIDGE_NAVSS_MCU_J7_UDMASS_PSILSS0_NAVSS_PSIL_AS_BRIDGE_EDC_CTRL_NAVSS_PSIL_SCR_E_GCLK_BUSECC_ENABLE_CLR — Interrupt Enable Clear Register for navss_mcu_j7_udmass_psilss0_navss_psil_as_bridge_navss_mcu_j7_udmass_psilss0_navss_psil_as_bridge_edc_ctrl_navss_psil_scr_e_gclk_busecc_pend (access R/W1TC)
  [1] NAVSS_MCU_J7_UDMASS_PSILSS0_NAVSS_PSIL_AS_BRIDGE_NAVSS_MCU_J7_UDMASS_PSILSS0_NAVSS_PSIL_AS_BRIDGE_EDC_CTRL_NAVSS_PSIL_E_GCLK_BUSECC_ENABLE_CLR — Interrupt Enable Clear Register for navss_mcu_j7_udmass_psilss0_navss_psil_as_bridge_navss_mcu_j7_udmass_psilss0_navss_psil_as_bridge_edc_ctrl_navss_psil_e_gclk_busecc_pend (access R/W1TC)
  [0] UDMASS_INTA0_GC_ECC_ENABLE_CLR — Interrupt Enable Clear Register for udmass_inta0_gc_ecc_pend (access R/W1TC)
0x1CC PAR_UDMASS__UDMASS_ECCAGGR0_CFG__REGS_ded_enable_clr_reg3 — Interrupt Enable Clear Register 3
  [1] NAVSS_MCU_J7_UDMASS_PSILSS0_CBASS_ETL_NAVSS_MCU_J7_UDMASS_PSILSS0_CBASS_ETL_VD2GCLK_EDC_CTRL_CBASS_INT_VD2GBUSECC_ENABLE_CLR — Interrupt Enable Clear Register for navss_mcu_j7_udmass_psilss0_cbass_etl_navss_mcu_j7_udmass_psilss0_cbass_etl_vd2gclk_edc_ctrl_cbass_int_vd2gbusecc_pend (access R/W1TC)
  [0] NAVSS_MCU_J7_UDMASS_PSILSS0_CBASS_ETL_NAVSS_MCU_J7_UDMASS_PSILSS0_CBASS_ETL_SCR3_SCR_NAVSS_MCU_J7_UDMASS_PSILSS0_CBASS_ETL_SCR3_SCR_EDC_CTRL_BUSECC_1_ENABLE_CLR — Interrupt Enable Clear Register for navss_mcu_j7_udmass_psilss0_cbass_etl_navss_mcu_j7_udmass_psilss0_cbass_etl_scr3_scr_navss_mcu_j7_udmass_psilss0_cbass_etl_scr3_scr_edc_ctrl_busecc_1_pend (access R/W1TC)
0x200 PAR_UDMASS__UDMASS_ECCAGGR0_CFG__REGS_aggr_enable_set — AGGR interrupt enable set Register
  [1] TIMEOUT — interrupt enable set for svbus timeout errors (access R/W1TS)
  [0] PARITY — interrupt enable set for parity errors (access R/W1TS)
0x204 PAR_UDMASS__UDMASS_ECCAGGR0_CFG__REGS_aggr_enable_clr — AGGR interrupt enable clear Register
  [1] TIMEOUT — interrupt enable clear for svbus timeout errors (access R/W1TC)
  [0] PARITY — interrupt enable clear for parity errors (access R/W1TC)
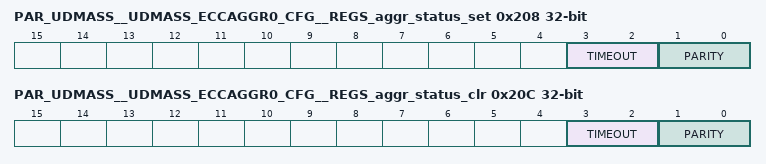
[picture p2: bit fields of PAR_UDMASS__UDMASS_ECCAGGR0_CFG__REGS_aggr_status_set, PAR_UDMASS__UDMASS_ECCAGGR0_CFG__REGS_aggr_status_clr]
0x208 PAR_UDMASS__UDMASS_ECCAGGR0_CFG__REGS_aggr_status_set — AGGR interrupt status set Register
  [3:2] TIMEOUT — interrupt status set for svbus timeout errors (access R/WI)
  [1:0] PARITY — interrupt status set for parity errors (access R/WI)
0x20C PAR_UDMASS__UDMASS_ECCAGGR0_CFG__REGS_aggr_status_clr — AGGR interrupt status clear Register
  [3:2] TIMEOUT — interrupt status clear for svbus timeout errors (access R/WD)
  [1:0] PARITY — interrupt status clear for parity errors (access R/WD)
